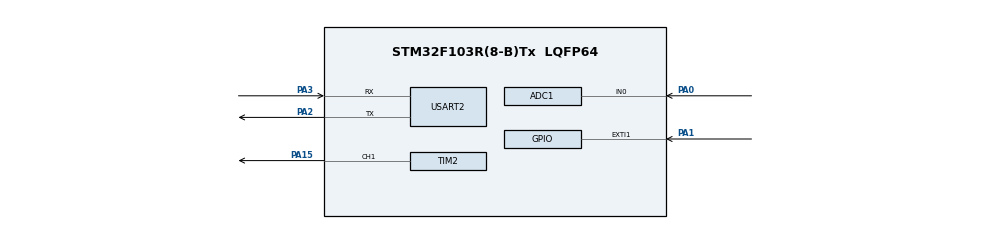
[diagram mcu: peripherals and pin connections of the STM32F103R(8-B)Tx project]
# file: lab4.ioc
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ADC1.Channel-2\#ChannelRegularConversion=ADC_CHANNEL_0
ADC1.NbrOfConversionFlag=1
ADC1.Rank-2\#ChannelRegularConversion=1
ADC1.SamplingTime-2\#ChannelRegularConversion=ADC_SAMPLETIME_1CYCLE_5
ADC1.master=1
Dma.ADC1.0.Direction=DMA_PERIPH_TO_MEMORY
Dma.ADC1.0.Instance=DMA1_Channel1
Dma.ADC1.0.MemDataAlignment=DMA_MDATAALIGN_HALFWORD
Dma.ADC1.0.MemInc=DMA_MINC_ENABLE
Dma.ADC1.0.Mode=DMA_NORMAL
Dma.ADC1.0.PeriphDataAlignment=DMA_PDATAALIGN_HALFWORD
Dma.ADC1.0.PeriphInc=DMA_PINC_DISABLE
Dma.ADC1.0.Priority=DMA_PRIORITY_LOW
Dma.Request0=ADC1
Mcu.Family=STM32F1
Mcu.Name=STM32F103R(8-B)Tx
Mcu.Package=LQFP64
NVIC.ADC1_2_IRQn=true\:0\:0\:false\:false\:true\:true\:true\:true
NVIC.DMA1_Channel1_IRQn=true\:0\:0\:false\:false\:true\:false\:true\:true
NVIC.EXTI1_IRQn=true\:0\:0\:false\:false\:true\:true\:true\:true
NVIC.PriorityGroup=NVIC_PRIORITYGROUP_4
NVIC.USART2_IRQn=true\:0\:0\:false\:false\:true\:true\:true\:true
PA0-WKUP.Signal=ADCx_IN0
PA1.Signal=GPXTI1
PA15.Signal=S_TIM2_CH1_ETR
PA2.Mode=Asynchronous
PA2.Signal=USART2_TX
PA3.Mode=Asynchronous
PA3.Signal=USART2_RX
PD0-OSC_IN.Mode=HSE-External-Oscillator
PD0-OSC_IN.Signal=RCC_OSC_IN
PD1-OSC_OUT.Mode=HSE-External-Oscillator
PD1-OSC_OUT.Signal=RCC_OSC_OUT
ProjectManager.HeapSize=0x200
ProjectManager.StackSize=0x400
ProjectManager.TargetToolchain=MDK-ARM V5.32
RCC.APB1Freq_Value=8000000
RCC.APB2Freq_Value=8000000
RCC.USBFreq_Value=8000000
SH.ADCx_IN0.0=ADC1_IN0,IN0
SH.S_TIM2_CH1_ETR.0=TIM2_CH1,PWM Generation1 CH1
TIM2.AutoReloadPreload=TIM_AUTORELOAD_PRELOAD_ENABLE
TIM2.Channel-PWM\ Generation1\ CH1=TIM_CHANNEL_1
USART2.VirtualMode=VM_ASYNC
VP_SYS_VS_ND.Mode=No_Debug
VP_TIM2_VS_ClockSourceINT.Mode=Internal
board=custom

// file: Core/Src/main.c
/* USER CODE BEGIN Header */
/**
  ******************************************************************************
  * @file           : main.c
  * @brief          : Main program body
  ******************************************************************************
  * @attention
  *
  * Copyright (c) 2022 STMicroelectronics.
  * All rights reserved.
  *
  * This software is licensed under terms that can be found in the LICENSE file
  * in the root directory of this software component.
  * If no LICENSE file comes with this software, it is provided AS-IS.
  *
  ******************************************************************************
  */
/* USER CODE END Header */
#include "main.h"

ADC_HandleTypeDef hadc1;
DMA_HandleTypeDef hdma_adc1;

TIM_HandleTypeDef htim2;

UART_HandleTypeDef huart2;

void SystemClock_Config(void);
static void MX_GPIO_Init(void);
static void MX_DMA_Init(void);
static void MX_ADC1_Init(void);
static void MX_TIM2_Init(void);
static void MX_USART2_UART_Init(void);

/* USER CODE BEGIN 0 */
uint32_t AD_RES = 0;
char data[5];
uint8_t flag = 0;
/* USER CODE END 0 */

int main(void)
{

  /* MCU Configuration--------------------------------------------------------*/

  /* Reset of all peripherals, Initializes the Flash interface and the Systick. */
  HAL_Init();

  /* Configure the system clock */
  SystemClock_Config();

  /* Initialize all configured peripherals */
  MX_GPIO_Init();
  MX_DMA_Init();
  MX_ADC1_Init();
  MX_TIM2_Init();
  MX_USART2_UART_Init();
  /* USER CODE BEGIN 2 */
	HAL_TIM_PWM_Start(&htim2, TIM_CHANNEL_1);
	// Calibrate The ADC On Power-Up For Better Accuracy
	HAL_ADCEx_Calibration_Start(&hadc1);
	HAL_UART_Transmit_IT(&huart2, (uint8_t*)data, sizeof(data));
  /* USER CODE END 2 */

  /* Infinite loop */
  while (1)
  {

    /* USER CODE BEGIN 3 */
		// Start ADC Conversion
    HAL_ADC_Start_DMA(&hadc1, &AD_RES, 1);
  }
  /* USER CODE END 3 */
}

void SystemClock_Config(void)
{
  RCC_OscInitTypeDef RCC_OscInitStruct = {0};
  RCC_ClkInitTypeDef RCC_ClkInitStruct = {0};
  RCC_PeriphCLKInitTypeDef PeriphClkInit = {0};

  /** Initializes the RCC Oscillators according to the specified parameters
  * in the RCC_OscInitTypeDef structure.
  */
  RCC_OscInitStruct.OscillatorType = RCC_OSCILLATORTYPE_HSI;
  RCC_OscInitStruct.HSIState = RCC_HSI_ON;
  RCC_OscInitStruct.HSICalibrationValue = RCC_HSICALIBRATION_DEFAULT;
  RCC_OscInitStruct.PLL.PLLState = RCC_PLL_NONE;
  if (HAL_RCC_OscConfig(&RCC_OscInitStruct) != HAL_OK)
  {
    Error_Handler();
  }

  /** Initializes the CPU, AHB and APB buses clocks
  */
  RCC_ClkInitStruct.ClockType = RCC_CLOCKTYPE_HCLK|RCC_CLOCKTYPE_SYSCLK
                              |RCC_CLOCKTYPE_PCLK1|RCC_CLOCKTYPE_PCLK2;
  RCC_ClkInitStruct.SYSCLKSource = RCC_SYSCLKSOURCE_HSI;
  RCC_ClkInitStruct.AHBCLKDivider = RCC_SYSCLK_DIV1;
  RCC_ClkInitStruct.APB1CLKDivider = RCC_HCLK_DIV1;
  RCC_ClkInitStruct.APB2CLKDivider = RCC_HCLK_DIV1;

  if (HAL_RCC_ClockConfig(&RCC_ClkInitStruct, FLASH_LATENCY_0) != HAL_OK)
  {
    Error_Handler();
  }
  PeriphClkInit.PeriphClockSelection = RCC_PERIPHCLK_ADC;
  PeriphClkInit.AdcClockSelection = RCC_ADCPCLK2_DIV2;
  if (HAL_RCCEx_PeriphCLKConfig(&PeriphClkInit) != HAL_OK)
  {
    Error_Handler();
  }
}

static void MX_ADC1_Init(void)
{

  ADC_ChannelConfTypeDef sConfig = {0};

  /** Common config
  */
  hadc1.Instance = ADC1;
  hadc1.Init.ScanConvMode = ADC_SCAN_DISABLE;
  hadc1.Init.ContinuousConvMode = DISABLE;
  hadc1.Init.DiscontinuousConvMode = DISABLE;
  hadc1.Init.ExternalTrigConv = ADC_SOFTWARE_START;
  hadc1.Init.DataAlign = ADC_DATAALIGN_RIGHT;
  hadc1.Init.NbrOfConversion = 1;
  if (HAL_ADC_Init(&hadc1) != HAL_OK)
  {
    Error_Handler();
  }

  /** Configure Regular Channel
  */
  sConfig.Channel = ADC_CHANNEL_0;
  sConfig.Rank = ADC_REGULAR_RANK_1;
  sConfig.SamplingTime = ADC_SAMPLETIME_1CYCLE_5;
  if (HAL_ADC_ConfigChannel(&hadc1, &sConfig) != HAL_OK)
  {
    Error_Handler();
  }

}

static void MX_TIM2_Init(void)
{

  TIM_ClockConfigTypeDef sClockSourceConfig = {0};
  TIM_MasterConfigTypeDef sMasterConfig = {0};
  TIM_OC_InitTypeDef sConfigOC = {0};

  htim2.Instance = TIM2;
  htim2.Init.Prescaler = 0;
  htim2.Init.CounterMode = TIM_COUNTERMODE_UP;
  htim2.Init.Period = 65535;
  htim2.Init.ClockDivision = TIM_CLOCKDIVISION_DIV1;
  htim2.Init.AutoReloadPreload = TIM_AUTORELOAD_PRELOAD_ENABLE;
  if (HAL_TIM_Base_Init(&htim2) != HAL_OK)
  {
    Error_Handler();
  }
  sClockSourceConfig.ClockSource = TIM_CLOCKSOURCE_INTERNAL;
  if (HAL_TIM_ConfigClockSource(&htim2, &sClockSourceConfig) != HAL_OK)
  {
    Error_Handler();
  }
  if (HAL_TIM_PWM_Init(&htim2) != HAL_OK)
  {
    Error_Handler();
  }
  sMasterConfig.MasterOutputTrigger = TIM_TRGO_RESET;
  sMasterConfig.MasterSlaveMode = TIM_MASTERSLAVEMODE_DISABLE;
  if (HAL_TIMEx_MasterConfigSynchronization(&htim2, &sMasterConfig) != HAL_OK)
  {
    Error_Handler();
  }
  sConfigOC.OCMode = TIM_OCMODE_PWM1;
  sConfigOC.Pulse = 0;
  sConfigOC.OCPolarity = TIM_OCPOLARITY_HIGH;
  sConfigOC.OCFastMode = TIM_OCFAST_DISABLE;
  if (HAL_TIM_PWM_ConfigChannel(&htim2, &sConfigOC, TIM_CHANNEL_1) != HAL_OK)
  {
    Error_Handler();
  }
  HAL_TIM_MspPostInit(&htim2);

}

static void MX_USART2_UART_Init(void)
{

  huart2.Instance = USART2;
  huart2.Init.BaudRate = 9600;
  huart2.Init.WordLength = UART_WORDLENGTH_8B;
  huart2.Init.StopBits = UART_STOPBITS_1;
  huart2.Init.Parity = UART_PARITY_NONE;
  huart2.Init.Mode = UART_MODE_TX_RX;
  huart2.Init.HwFlowCtl = UART_HWCONTROL_NONE;
  huart2.Init.OverSampling = UART_OVERSAMPLING_16;
  if (HAL_UART_Init(&huart2) != HAL_OK)
  {
    Error_Handler();
  }

}

static void MX_DMA_Init(void)
{

  /* DMA controller clock enable */
  __HAL_RCC_DMA1_CLK_ENABLE();

  /* DMA interrupt init */
  /* DMA1_Channel1_IRQn interrupt configuration */
  HAL_NVIC_SetPriority(DMA1_Channel1_IRQn, 0, 0);
  HAL_NVIC_EnableIRQ(DMA1_Channel1_IRQn);

}

static void MX_GPIO_Init(void)
{
  GPIO_InitTypeDef GPIO_InitStruct = {0};

  /* GPIO Ports Clock Enable */
  __HAL_RCC_GPIOD_CLK_ENABLE();
  __HAL_RCC_GPIOA_CLK_ENABLE();

  /*Configure GPIO pin : PA1 */
  GPIO_InitStruct.Pin = GPIO_PIN_1;
  GPIO_InitStruct.Mode = GPIO_MODE_IT_RISING;
  GPIO_InitStruct.Pull = GPIO_NOPULL;
  HAL_GPIO_Init(GPIOA, &GPIO_InitStruct);

  /* EXTI interrupt init*/
  HAL_NVIC_SetPriority(EXTI1_IRQn, 0, 0);
  HAL_NVIC_EnableIRQ(EXTI1_IRQn);

}

/* USER CODE BEGIN 4 */
void HAL_UART_TxCpltCallback(UART_HandleTypeDef* huart)
{
	if(flag == 0){
		sprintf(data, "%d", AD_RES);
	}

	HAL_UART_Transmit_IT(&huart2, (uint8_t*)data, sizeof(data));
}

void HAL_ADC_ConvCpltCallback(ADC_HandleTypeDef* hadc)
{
    // Conversion Complete & DMA Transfer Complete As Well
    // Update The PWM Duty Cycle With Latest ADC Conversion Result
    TIM2->CCR1 = (AD_RES<<4);
}
/* USER CODE END 4 */

void Error_Handler(void)
{
  __disable_irq();
  while (1)
  {
  }
}
